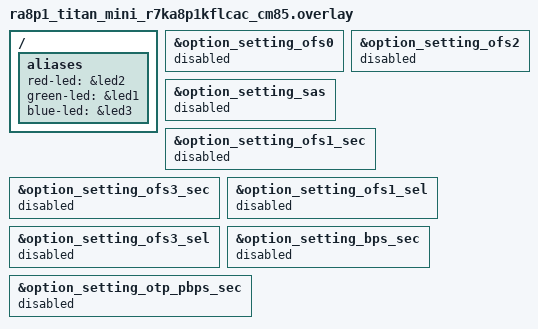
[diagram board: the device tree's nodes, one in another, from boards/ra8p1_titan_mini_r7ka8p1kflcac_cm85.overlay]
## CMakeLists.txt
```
# SPDX-License-Identifier: Apache-2.0

cmake_minimum_required(VERSION 3.21.0)


find_package(Zephyr REQUIRED HINTS $ENV{ZEPHYR_BASE})
project(rgb_led)

target_sources(app PRIVATE src/main.c)
```

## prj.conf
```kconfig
# 串口控制台、GPIO 已由板 defconfig 打开。
CONFIG_PRINTK=y

# 板 dts 已选 zephyr,shell-uart = &uart2，开 SHELL 后串口后端会自动跟上。
CONFIG_SHELL=y
CONFIG_KERNEL_SHELL=y
CONFIG_DEVICE_SHELL=y
```

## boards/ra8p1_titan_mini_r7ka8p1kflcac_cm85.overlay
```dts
/*
 * Titan Mini 板级默认已经够用：
 *   - 控制台：SCI2 / UART2，P801=TX、P802=RX，115200
 *   - RGB LED：gpio-leds 的 led1/led2/led3（P108 绿、P109 红、P110 蓝，低电平点亮）
 *
 * 本 overlay 只做两件板文件不会替应用做的事：
 *   1. 给三颗灯起应用侧别名，main.c 用颜色名去取
 *   2. 关掉 Option-setting / OTP 节点，避免链接进配置区（下载红线）
 *
 * 不要在这里重配 UART，也不要把这三颗灯改成 PWM。
 * 官方 FSP PWM 例程用的是 P714（GPT12），不是板上 RGB。
 */

/ {
	aliases {
		red-led = &led2;
		green-led = &led1;
		blue-led = &led3;
	};
};

&option_setting_ofs0 { status = "disabled"; };
&option_setting_ofs2 { status = "disabled"; };
&option_setting_sas { status = "disabled"; };
&option_setting_ofs1_sec { status = "disabled"; };
&option_setting_ofs3_sec { status = "disabled"; };
&option_setting_ofs1_sel { status = "disabled"; };
&option_setting_ofs3_sel { status = "disabled"; };
&option_setting_bps_sec { status = "disabled"; };
&option_setting_otp_pbps_sec { status = "disabled"; };
```

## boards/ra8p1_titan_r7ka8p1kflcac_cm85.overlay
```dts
/*
 * Titan Mini 板级默认已经够用：
 *   - 控制台：SCI2 / UART2，P801=TX、P802=RX，115200
 *   - RGB LED：gpio-leds 的 led1/led2/led3（P108 绿、P109 红、P110 蓝，低电平点亮）
 *
 * 本 overlay 只做两件板文件不会替应用做的事：
 *   1. 给三颗灯起应用侧别名，main.c 用颜色名去取
 *   2. 关掉 Option-setting / OTP 节点，避免链接进配置区（下载红线）
 *
 * 不要在这里重配 UART，也不要把这三颗灯改成 PWM。
 * 官方 FSP PWM 例程用的是 P714（GPT12），不是板上 RGB。
 */

/ {
	aliases {
		red-led = &led_red;
		green-led = &led_green;
		blue-led = &led_blue;
	};
};


&option_setting_ofs0 { status = "disabled"; };
&option_setting_ofs2 { status = "disabled"; };
&option_setting_sas { status = "disabled"; };
&option_setting_ofs1_sec { status = "disabled"; };
&option_setting_ofs3_sec { status = "disabled"; };
&option_setting_ofs1_sel { status = "disabled"; };
&option_setting_ofs3_sel { status = "disabled"; };
&option_setting_bps_sec { status = "disabled"; };
&option_setting_otp_pbps_sec { status = "disabled"; };
```

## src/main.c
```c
/*
 * SPDX-License-Identifier: Apache-2.0
 *
 * Titan Mini 板载 RGB LED 演示。
 *
 * 灯是共阳 GPIO，不是 PWM：
 *   红 P109 / led2，绿 P108 / led1，蓝 P110 / led3，低电平点亮。
 * 板 DTS 已经写成 gpio-leds + GPIO_ACTIVE_LOW，所以
 * gpio_pin_set_dt(..., 1) 表示逻辑点亮，不必自己反相。
 *
 * 控制台和 shell 都走板默认 UART2（SCI2，P801/P802，115200）。
 */

#include <errno.h>
#include <stddef.h>
#include <stdint.h>

#include <zephyr/kernel.h>
#include <zephyr/sys/printk.h>
#include <zephyr/drivers/gpio.h>

/* 应用侧别名在 app.overlay 里接到板级 led1/led2/led3。 */
static const struct gpio_dt_spec red_led = GPIO_DT_SPEC_GET(DT_ALIAS(red_led), gpios);
static const struct gpio_dt_spec green_led = GPIO_DT_SPEC_GET(DT_ALIAS(green_led), gpios);
static const struct gpio_dt_spec blue_led = GPIO_DT_SPEC_GET(DT_ALIAS(blue_led), gpios);

struct rgb_color {
	const char *name;
	uint8_t r;
	uint8_t g;
	uint8_t b;
};

/* 1 = 亮，0 = 灭。顺序与官方 RT-Thread RGB 例程一致。 */
static const struct rgb_color palette[] = {
	{ "off",    0, 0, 0 },
	{ "red",    1, 0, 0 },
	{ "green",  0, 1, 0 },
	{ "blue",   0, 0, 1 },
	{ "yellow", 1, 1, 0 },
	{ "cyan",   0, 1, 1 },
	{ "magenta",1, 0, 1 },
	{ "white",  1, 1, 1 },
};

/**
 * @brief 把一颗 gpio-leds 子节点配成输出。
 *
 * gpio_is_ready_dt / gpio_pin_configure_dt 是应用可直接调用的 Zephyr GPIO API，
 * 不是 RA 寄存器驱动入口。
 */
static int led_setup(const struct gpio_dt_spec *led, const char *name)
{
	int ret;

	if (!gpio_is_ready_dt(led)) {
		printk("Error: %s GPIO is not ready\n", name);
		return -ENODEV;
	}

	ret = gpio_pin_configure_dt(led, GPIO_OUTPUT_INACTIVE);
	if (ret < 0) {
		printk("Error: failed to configure %s (%d)\n", name, ret);
		return ret;
	}

	return 0;
}

/** @brief 按逻辑亮灭写三通道。gpio_pin_set_dt 是应用 API。 */
static int rgb_set(uint8_t r, uint8_t g, uint8_t b)
{
	int ret;

	ret = gpio_pin_set_dt(&red_led, r);
	if (ret < 0) {
		return ret;
	}
	ret = gpio_pin_set_dt(&green_led, g);
	if (ret < 0) {
		return ret;
	}
	return gpio_pin_set_dt(&blue_led, b);
}

int main(void)
{
	int ret;

	printk("Titan Mini RGB LED (GPIO, UART2). Shell prompt: uart:~$\n");
	printk("Type help, kernel stacks, or device list\n");

	if (led_setup(&red_led, "red") ||
	    led_setup(&green_led, "green") ||
	    led_setup(&blue_led, "blue")) {
		return 0;
	}

	while (1) {
		for (size_t i = 0; i < ARRAY_SIZE(palette); i++) {
			ret = rgb_set(palette[i].r, palette[i].g, palette[i].b);
			if (ret < 0) {
				printk("Error: RGB write failed (%d)\n", ret);
				return 0;
			}
			k_msleep(80);
		}
	}

	return 0;
}
```
